AUTOSAR XML (schema 00044)
package /E40_Platform_System_SystemPackage/Components
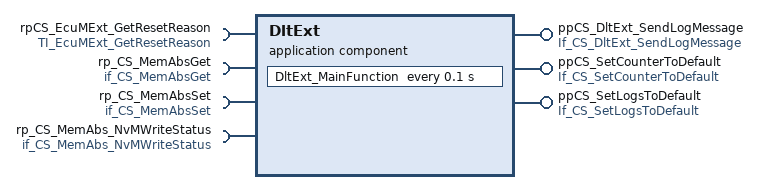
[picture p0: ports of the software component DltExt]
  application sw component type DltExt
    provide port ppCS_DltExt_SendLogMessage: server-com-spec{operation=SendLogMessage, queue-length=1}, provided-interface=If_CS_DltExt_SendLogMessage
    provide port ppCS_SetCounterToDefault: server-com-spec{operation=SetCounterToDefault, queue-length=1}, provided-interface=If_CS_SetCounterToDefault
    provide port ppCS_SetLogsToDefault: server-com-spec{operation=SetLogsToDefault, queue-length=1}, provided-interface=If_CS_SetLogsToDefault
    4 x require port:
      rpCS_EcuMExt_GetResetReason: client-com-spec=EcuMExt_GetResetReason, required-interface=TI_EcuMExt_GetResetReason
      rp_CS_MemAbsGet: required-interface=if_CS_MemAbsGet
        required-com-specs:
          Get_BsConst_Audio_Element
          Get_BsConst_Communication_Element
          Get_BsConst_EngOffTimer_Element
          Get_BsConst_FuelGauge_Element
          Get_BsConst_Illumination_Element
          Get_BsConst_OilGauge_Element
          Get_BsConst_PowerGauge_Element
          Get_BsConst_Power_Element
          Get_BsConst_RealTimeClock_Element
          Get_BsConst_ServiceReminder_Element
          Get_BsConst_SpeedoGauge_Element
          Get_BsConst_TachoGauge_Element
          Get_BsConst_TempGauge_Element
          Get_BsConst_TripComputer_Element
          Get_BsConst_Warning_Element
          Get_BsCys_Certicificate_Element
          Get_BsDiag_Dtc_Element
          Get_BsDiag_ErrorRecord_Element
          Get_BsFuSa_Audio_Element
          Get_BsFuSa_Communication_Element
          Get_BsFuSa_Config_Element
          Get_BsFuSa_Display_Element
          Get_BsFuSa_Power_Element
          Get_BsFuSa_Warning_Element
          Get_BsFusa_Fota_Element
          Get_BsReten_Audio_Element
          Get_BsReten_Communication_Element
          Get_BsReten_Display_Element
          Get_BsReten_Gauges_Element
          Get_BsReten_Illumination_Element
          Get_BsReten_Odometer_Element
          Get_BsReten_Personalization_Element
          Get_BsReten_Power_Element
          Get_BsReten_RealTimeClock_Element
          Get_BsReten_Tripcomputer_Element
          Get_BsReten_VisDlt_Element
          Get_BsReten_Warning_Element
          Get_BsRt_CusDlt_Element
          Get_BsRt_FuelGauge_Element
          Get_BsRt_Illumination_Element
          Get_BsRt_Odometer_Element
          Get_BsRt_OilGauge_Element
          Get_BsRt_Personalization_Element
          Get_BsRt_PowerGauge_Element
          Get_BsRt_RealTimeClock_Element
          Get_BsRt_SpeedoGauge_Element
          Get_BsRt_TachoGauge_Element
          Get_BsRt_TempGauge_Element
          Get_BsRt_TripComputer_Element
          Get_BsRt_Warning_Element
          Get_BsShare_EcuPartNumber_Element
          Get_BsShare_SwUpdFotaFinPrint_Element
          Get_BsShare_SwUpdFotaMode_Element
          Get_BsShare_SwUpdFotaStatus_Element
          Get_BsShare_SwUpdFotadecrypt_Element
          Get_BsShare_SwUpdReflash_Element
          Get_BsShare_VehicleConfig_Element
          Get_BsShare_VisMeet_Element
          Get_RefCys_Certicificate1_Element
          Get_RefCys_Certicificate_Element
      rp_CS_MemAbsSet: required-interface=if_CS_MemAbsSet
        required-com-specs:
          Set_BsConst_Audio_Element
          Set_BsConst_Communication_Element
          Set_BsConst_EngOffTimer_Element
          Set_BsConst_FuelGauge_Element
          Set_BsConst_Illumination_Element
          Set_BsConst_OilGauge_Element
          Set_BsConst_PowerGauge_Element
          Set_BsConst_Power_Element
          Set_BsConst_RealTimeClock_Element
          Set_BsConst_ServiceReminder_Element
          Set_BsConst_SpeedoGauge_Element
          Set_BsConst_TachoGauge_Element
          Set_BsConst_TempGauge_Element
          Set_BsConst_TripComputer_Element
          Set_BsConst_Warning_Element
          Set_BsCys_Certicificate_Element
          Set_BsDiag_Dtc_Element
          Set_BsDiag_ErrorRecord_Element
          Set_BsFuSa_Audio_Element
          Set_BsFuSa_Communication_Element
          Set_BsFuSa_Config_Element
          Set_BsFuSa_Display_Element
          Set_BsFuSa_Power_Element
          Set_BsFuSa_Warning_Element
          Set_BsFusa_Fota_Element
          Set_BsReten_Audio_Element
          Set_BsReten_Communication_Element
          Set_BsReten_Display_Element
          Set_BsReten_Gauges_Element
          Set_BsReten_Illumination_Element
          Set_BsReten_Odometer_Element
          Set_BsReten_Personalization_Element
          Set_BsReten_Power_Element
          Set_BsReten_RealTimeClock_Element
          Set_BsReten_Tripcomputer_Element
          Set_BsReten_VisDlt_Element
          Set_BsReten_Warning_Element
          Set_BsRt_CusDlt_Element
          Set_BsRt_FuelGauge_Element
          Set_BsRt_Illumination_Element
          Set_BsRt_Odometer_Element
          Set_BsRt_OilGauge_Element
          Set_BsRt_Personalization_Element
          Set_BsRt_PowerGauge_Element
          Set_BsRt_RealTimeClock_Element
          Set_BsRt_SpeedoGauge_Element
          Set_BsRt_TachoGauge_Element
          Set_BsRt_TempGauge_Element
          Set_BsRt_TripComputer_Element
          Set_BsRt_Warning_Element
          Set_BsShare_EcuPartNumber_Element
          Set_BsShare_SwUpdFotaFinPrint_Element
          Set_BsShare_SwUpdFotaMode_Element
          Set_BsShare_SwUpdFotaStatus_Element
          Set_BsShare_SwUpdFotadecrypt_Element
          Set_BsShare_SwUpdReflash_Element
          Set_BsShare_VehicleConfig_Element
          Set_BsShare_VisMeet_Element
          Set_RefCys_Certicificate1_Element
          Set_RefCys_Certicificate_Element
      rp_CS_MemAbs_NvMWriteStatus: client-com-spec=NvmWriteStatus, required-interface=if_CS_MemAbs_NvMWriteStatus
    behavior IB_DltExt
      timing event TEDltExt_MainFunction: start-on-event=DltExt_MainFunction, period=0.1
      operation invoked event OIE_ppCS_DltExt_SendLogMessage_DltExt_SendLogMessageTrigBySendLogMessage: start-on-event=DltExt_SendLogMessage, operation=ppCS_DltExt_SendLogMessage.SendLogMessage
      operation invoked event OIE_ppCS_SetCounterToDefault_DltExt_SetCounterToDefaultTrigBySetCounterToDefault: start-on-event=DltExt_SetCounterToDefault, operation=ppCS_SetCounterToDefault.SetCounterToDefault
      operation invoked event OIE_ppCS_SetLogsToDefault_DltExt_SetLogsToDefaultTrigBySetLogsToDefault: start-on-event=DltExt_SetLogsToDefault, operation=ppCS_SetLogsToDefault.SetLogsToDefault
      port-api-options:
        enable-take-address=false, indirect-api=false, port=ppCS_DltExt_SendLogMessage
        enable-take-address=false, indirect-api=false, port=ppCS_SetCounterToDefault
        enable-take-address=false, indirect-api=false, port=ppCS_SetLogsToDefault
        enable-take-address=false, indirect-api=false, port=rpCS_EcuMExt_GetResetReason
        enable-take-address=false, indirect-api=false, port=rp_CS_MemAbsGet
        enable-take-address=false, indirect-api=false, port=rp_CS_MemAbsSet
        enable-take-address=false, indirect-api=false, port=rp_CS_MemAbs_NvMWriteStatus
      4 x runnable, all with can-be-invoked-concurrently=true:
        DltExt_MainFunction
          122 x sync call:
            OA_rpCS_EcuMExt_GetResetReason_EcuMExt_GetResetReason: operation=rpCS_EcuMExt_GetResetReason.EcuMExt_GetResetReason
            OA_rp_CS_MemAbsGet_Get_BsShare_SwUpdReflash_Element: operation=rp_CS_MemAbsGet.Get_BsShare_SwUpdReflash_Element
            OA_rp_CS_MemAbsGet_Get_BsShare_SwUpdFotaMode_Element: operation=rp_CS_MemAbsGet.Get_BsShare_SwUpdFotaMode_Element
            OA_rp_CS_MemAbsGet_Get_BsShare_SwUpdFotaFinPrint_Element: operation=rp_CS_MemAbsGet.Get_BsShare_SwUpdFotaFinPrint_Element
            OA_rp_CS_MemAbsGet_Get_BsShare_SwUpdFotaStatus_Element: operation=rp_CS_MemAbsGet.Get_BsShare_SwUpdFotaStatus_Element
            OA_rp_CS_MemAbsGet_Get_BsShare_SwUpdFotadecrypt_Element: operation=rp_CS_MemAbsGet.Get_BsShare_SwUpdFotadecrypt_Element
            OA_rp_CS_MemAbsGet_Get_BsShare_EcuPartNumber_Element: operation=rp_CS_MemAbsGet.Get_BsShare_EcuPartNumber_Element
            OA_rp_CS_MemAbsGet_Get_BsShare_VisMeet_Element: operation=rp_CS_MemAbsGet.Get_BsShare_VisMeet_Element
            OA_rp_CS_MemAbsGet_Get_BsShare_VehicleConfig_Element: operation=rp_CS_MemAbsGet.Get_BsShare_VehicleConfig_Element
            OA_rp_CS_MemAbsGet_Get_BsConst_SpeedoGauge_Element: operation=rp_CS_MemAbsGet.Get_BsConst_SpeedoGauge_Element
            OA_rp_CS_MemAbsGet_Get_BsConst_TachoGauge_Element: operation=rp_CS_MemAbsGet.Get_BsConst_TachoGauge_Element
            OA_rp_CS_MemAbsGet_Get_BsConst_FuelGauge_Element: operation=rp_CS_MemAbsGet.Get_BsConst_FuelGauge_Element
            OA_rp_CS_MemAbsGet_Get_BsConst_TempGauge_Element: operation=rp_CS_MemAbsGet.Get_BsConst_TempGauge_Element
            OA_rp_CS_MemAbsGet_Get_BsConst_PowerGauge_Element: operation=rp_CS_MemAbsGet.Get_BsConst_PowerGauge_Element
            OA_rp_CS_MemAbsGet_Get_BsConst_OilGauge_Element: operation=rp_CS_MemAbsGet.Get_BsConst_OilGauge_Element
            OA_rp_CS_MemAbsGet_Get_BsConst_TripComputer_Element: operation=rp_CS_MemAbsGet.Get_BsConst_TripComputer_Element
            OA_rp_CS_MemAbsGet_Get_BsConst_Illumination_Element: operation=rp_CS_MemAbsGet.Get_BsConst_Illumination_Element
            OA_rp_CS_MemAbsGet_Get_BsConst_Audio_Element: operation=rp_CS_MemAbsGet.Get_BsConst_Audio_Element
            OA_rp_CS_MemAbsGet_Get_BsConst_Warning_Element: operation=rp_CS_MemAbsGet.Get_BsConst_Warning_Element
            OA_rp_CS_MemAbsGet_Get_BsConst_RealTimeClock_Element: operation=rp_CS_MemAbsGet.Get_BsConst_RealTimeClock_Element
            OA_rp_CS_MemAbsGet_Get_BsConst_Communication_Element: operation=rp_CS_MemAbsGet.Get_BsConst_Communication_Element
            OA_rp_CS_MemAbsGet_Get_BsConst_Power_Element: operation=rp_CS_MemAbsGet.Get_BsConst_Power_Element
            OA_rp_CS_MemAbsGet_Get_BsConst_ServiceReminder_Element: operation=rp_CS_MemAbsGet.Get_BsConst_ServiceReminder_Element
            OA_rp_CS_MemAbsGet_Get_BsConst_EngOffTimer_Element: operation=rp_CS_MemAbsGet.Get_BsConst_EngOffTimer_Element
            OA_rp_CS_MemAbsGet_Get_BsFuSa_Warning_Element: operation=rp_CS_MemAbsGet.Get_BsFuSa_Warning_Element
            OA_rp_CS_MemAbsGet_Get_BsFuSa_Power_Element: operation=rp_CS_MemAbsGet.Get_BsFuSa_Power_Element
            OA_rp_CS_MemAbsGet_Get_BsFuSa_Display_Element: operation=rp_CS_MemAbsGet.Get_BsFuSa_Display_Element
            OA_rp_CS_MemAbsGet_Get_BsFuSa_Audio_Element: operation=rp_CS_MemAbsGet.Get_BsFuSa_Audio_Element
            OA_rp_CS_MemAbsGet_Get_BsFuSa_Communication_Element: operation=rp_CS_MemAbsGet.Get_BsFuSa_Communication_Element
            OA_rp_CS_MemAbsGet_Get_BsFusa_Fota_Element: operation=rp_CS_MemAbsGet.Get_BsFusa_Fota_Element
            OA_rp_CS_MemAbsGet_Get_BsFuSa_Config_Element: operation=rp_CS_MemAbsGet.Get_BsFuSa_Config_Element
            OA_rp_CS_MemAbsGet_Get_BsCys_Certicificate_Element: operation=rp_CS_MemAbsGet.Get_BsCys_Certicificate_Element
            OA_rp_CS_MemAbsGet_Get_RefCys_Certicificate_Element: operation=rp_CS_MemAbsGet.Get_RefCys_Certicificate_Element
            OA_rp_CS_MemAbsGet_Get_RefCys_Certicificate1_Element: operation=rp_CS_MemAbsGet.Get_RefCys_Certicificate1_Element
            OA_rp_CS_MemAbsGet_Get_BsRt_Odometer_Element: operation=rp_CS_MemAbsGet.Get_BsRt_Odometer_Element
            OA_rp_CS_MemAbsGet_Get_BsRt_SpeedoGauge_Element: operation=rp_CS_MemAbsGet.Get_BsRt_SpeedoGauge_Element
            OA_rp_CS_MemAbsGet_Get_BsRt_TachoGauge_Element: operation=rp_CS_MemAbsGet.Get_BsRt_TachoGauge_Element
            OA_rp_CS_MemAbsGet_Get_BsRt_FuelGauge_Element: operation=rp_CS_MemAbsGet.Get_BsRt_FuelGauge_Element
            OA_rp_CS_MemAbsGet_Get_BsRt_TempGauge_Element: operation=rp_CS_MemAbsGet.Get_BsRt_TempGauge_Element
            OA_rp_CS_MemAbsGet_Get_BsRt_PowerGauge_Element: operation=rp_CS_MemAbsGet.Get_BsRt_PowerGauge_Element
            OA_rp_CS_MemAbsGet_Get_BsRt_OilGauge_Element: operation=rp_CS_MemAbsGet.Get_BsRt_OilGauge_Element
            OA_rp_CS_MemAbsGet_Get_BsRt_TripComputer_Element: operation=rp_CS_MemAbsGet.Get_BsRt_TripComputer_Element
            OA_rp_CS_MemAbsGet_Get_BsRt_Warning_Element: operation=rp_CS_MemAbsGet.Get_BsRt_Warning_Element
            OA_rp_CS_MemAbsGet_Get_BsRt_RealTimeClock_Element: operation=rp_CS_MemAbsGet.Get_BsRt_RealTimeClock_Element
            OA_rp_CS_MemAbsGet_Get_BsRt_Personalization_Element: operation=rp_CS_MemAbsGet.Get_BsRt_Personalization_Element
            OA_rp_CS_MemAbsGet_Get_BsRt_Illumination_Element: operation=rp_CS_MemAbsGet.Get_BsRt_Illumination_Element
            OA_rp_CS_MemAbsGet_Get_BsRt_CusDlt_Element: operation=rp_CS_MemAbsGet.Get_BsRt_CusDlt_Element
            OA_rp_CS_MemAbsGet_Get_BsReten_Odometer_Element: operation=rp_CS_MemAbsGet.Get_BsReten_Odometer_Element
            OA_rp_CS_MemAbsGet_Get_BsReten_Gauges_Element: operation=rp_CS_MemAbsGet.Get_BsReten_Gauges_Element
            OA_rp_CS_MemAbsGet_Get_BsReten_Tripcomputer_Element: operation=rp_CS_MemAbsGet.Get_BsReten_Tripcomputer_Element
            OA_rp_CS_MemAbsGet_Get_BsReten_Illumination_Element: operation=rp_CS_MemAbsGet.Get_BsReten_Illumination_Element
            OA_rp_CS_MemAbsGet_Get_BsReten_Audio_Element: operation=rp_CS_MemAbsGet.Get_BsReten_Audio_Element
            OA_rp_CS_MemAbsGet_Get_BsReten_Warning_Element: operation=rp_CS_MemAbsGet.Get_BsReten_Warning_Element
            OA_rp_CS_MemAbsGet_Get_BsReten_RealTimeClock_Element: operation=rp_CS_MemAbsGet.Get_BsReten_RealTimeClock_Element
            OA_rp_CS_MemAbsGet_Get_BsReten_Communication_Element: operation=rp_CS_MemAbsGet.Get_BsReten_Communication_Element
            OA_rp_CS_MemAbsGet_Get_BsReten_Personalization_Element: operation=rp_CS_MemAbsGet.Get_BsReten_Personalization_Element
            OA_rp_CS_MemAbsGet_Get_BsReten_VisDlt_Element: operation=rp_CS_MemAbsGet.Get_BsReten_VisDlt_Element
            OA_rp_CS_MemAbsGet_Get_BsReten_Power_Element: operation=rp_CS_MemAbsGet.Get_BsReten_Power_Element
            OA_rp_CS_MemAbsGet_Get_BsReten_Display_Element: operation=rp_CS_MemAbsGet.Get_BsReten_Display_Element
            OA_rp_CS_MemAbsGet_Get_BsDiag_ErrorRecord_Element: operation=rp_CS_MemAbsGet.Get_BsDiag_ErrorRecord_Element
            OA_rp_CS_MemAbsGet_Get_BsDiag_Dtc_Element: operation=rp_CS_MemAbsGet.Get_BsDiag_Dtc_Element
            OA_rp_CS_MemAbsSet_Set_BsShare_SwUpdReflash_Element: operation=rp_CS_MemAbsSet.Set_BsShare_SwUpdReflash_Element
            OA_rp_CS_MemAbsSet_Set_BsShare_SwUpdFotaMode_Element: operation=rp_CS_MemAbsSet.Set_BsShare_SwUpdFotaMode_Element
            OA_rp_CS_MemAbsSet_Set_BsShare_SwUpdFotaFinPrint_Element: operation=rp_CS_MemAbsSet.Set_BsShare_SwUpdFotaFinPrint_Element
            OA_rp_CS_MemAbsSet_Set_BsShare_SwUpdFotaStatus_Element: operation=rp_CS_MemAbsSet.Set_BsShare_SwUpdFotaStatus_Element
            OA_rp_CS_MemAbsSet_Set_BsShare_SwUpdFotadecrypt_Element: operation=rp_CS_MemAbsSet.Set_BsShare_SwUpdFotadecrypt_Element
            OA_rp_CS_MemAbsSet_Set_BsShare_EcuPartNumber_Element: operation=rp_CS_MemAbsSet.Set_BsShare_EcuPartNumber_Element
            OA_rp_CS_MemAbsSet_Set_BsShare_VisMeet_Element: operation=rp_CS_MemAbsSet.Set_BsShare_VisMeet_Element
            OA_rp_CS_MemAbsSet_Set_BsShare_VehicleConfig_Element: operation=rp_CS_MemAbsSet.Set_BsShare_VehicleConfig_Element
            OA_rp_CS_MemAbsSet_Set_BsConst_SpeedoGauge_Element: operation=rp_CS_MemAbsSet.Set_BsConst_SpeedoGauge_Element
            OA_rp_CS_MemAbsSet_Set_BsConst_TachoGauge_Element: operation=rp_CS_MemAbsSet.Set_BsConst_TachoGauge_Element
            OA_rp_CS_MemAbsSet_Set_BsConst_FuelGauge_Element: operation=rp_CS_MemAbsSet.Set_BsConst_FuelGauge_Element
            OA_rp_CS_MemAbsSet_Set_BsConst_TempGauge_Element: operation=rp_CS_MemAbsSet.Set_BsConst_TempGauge_Element
            OA_rp_CS_MemAbsSet_Set_BsConst_PowerGauge_Element: operation=rp_CS_MemAbsSet.Set_BsConst_PowerGauge_Element
            OA_rp_CS_MemAbsSet_Set_BsConst_OilGauge_Element: operation=rp_CS_MemAbsSet.Set_BsConst_OilGauge_Element
            OA_rp_CS_MemAbsSet_Set_BsConst_TripComputer_Element: operation=rp_CS_MemAbsSet.Set_BsConst_TripComputer_Element
            OA_rp_CS_MemAbsSet_Set_BsConst_Illumination_Element: operation=rp_CS_MemAbsSet.Set_BsConst_Illumination_Element
            OA_rp_CS_MemAbsSet_Set_BsConst_Audio_Element: operation=rp_CS_MemAbsSet.Set_BsConst_Audio_Element
            OA_rp_CS_MemAbsSet_Set_BsConst_Warning_Element: operation=rp_CS_MemAbsSet.Set_BsConst_Warning_Element
            OA_rp_CS_MemAbsSet_Set_BsConst_RealTimeClock_Element: operation=rp_CS_MemAbsSet.Set_BsConst_RealTimeClock_Element
            OA_rp_CS_MemAbsSet_Set_BsConst_Communication_Element: operation=rp_CS_MemAbsSet.Set_BsConst_Communication_Element
            OA_rp_CS_MemAbsSet_Set_BsConst_Power_Element: operation=rp_CS_MemAbsSet.Set_BsConst_Power_Element
            OA_rp_CS_MemAbsSet_Set_BsConst_ServiceReminder_Element: operation=rp_CS_MemAbsSet.Set_BsConst_ServiceReminder_Element
            OA_rp_CS_MemAbsSet_Set_BsConst_EngOffTimer_Element: operation=rp_CS_MemAbsSet.Set_BsConst_EngOffTimer_Element
            OA_rp_CS_MemAbsSet_Set_BsFuSa_Warning_Element: operation=rp_CS_MemAbsSet.Set_BsFuSa_Warning_Element
            OA_rp_CS_MemAbsSet_Set_BsFuSa_Power_Element: operation=rp_CS_MemAbsSet.Set_BsFuSa_Power_Element
            OA_rp_CS_MemAbsSet_Set_BsFuSa_Display_Element: operation=rp_CS_MemAbsSet.Set_BsFuSa_Display_Element
            OA_rp_CS_MemAbsSet_Set_BsFuSa_Audio_Element: operation=rp_CS_MemAbsSet.Set_BsFuSa_Audio_Element
            OA_rp_CS_MemAbsSet_Set_BsFuSa_Communication_Element: operation=rp_CS_MemAbsSet.Set_BsFuSa_Communication_Element
            OA_rp_CS_MemAbsSet_Set_BsFusa_Fota_Element: operation=rp_CS_MemAbsSet.Set_BsFusa_Fota_Element
            OA_rp_CS_MemAbsSet_Set_BsFuSa_Config_Element: operation=rp_CS_MemAbsSet.Set_BsFuSa_Config_Element
            OA_rp_CS_MemAbsSet_Set_BsCys_Certicificate_Element: operation=rp_CS_MemAbsSet.Set_BsCys_Certicificate_Element
            OA_rp_CS_MemAbsSet_Set_RefCys_Certicificate_Element: operation=rp_CS_MemAbsSet.Set_RefCys_Certicificate_Element
            OA_rp_CS_MemAbsSet_Set_RefCys_Certicificate1_Element: operation=rp_CS_MemAbsSet.Set_RefCys_Certicificate1_Element
            OA_rp_CS_MemAbsSet_Set_BsRt_Odometer_Element: operation=rp_CS_MemAbsSet.Set_BsRt_Odometer_Element
            OA_rp_CS_MemAbsSet_Set_BsRt_SpeedoGauge_Element: operation=rp_CS_MemAbsSet.Set_BsRt_SpeedoGauge_Element
            OA_rp_CS_MemAbsSet_Set_BsRt_TachoGauge_Element: operation=rp_CS_MemAbsSet.Set_BsRt_TachoGauge_Element
            OA_rp_CS_MemAbsSet_Set_BsRt_FuelGauge_Element: operation=rp_CS_MemAbsSet.Set_BsRt_FuelGauge_Element
            OA_rp_CS_MemAbsSet_Set_BsRt_TempGauge_Element: operation=rp_CS_MemAbsSet.Set_BsRt_TempGauge_Element
            OA_rp_CS_MemAbsSet_Set_BsRt_PowerGauge_Element: operation=rp_CS_MemAbsSet.Set_BsRt_PowerGauge_Element
            OA_rp_CS_MemAbsSet_Set_BsRt_OilGauge_Element: operation=rp_CS_MemAbsSet.Set_BsRt_OilGauge_Element
            OA_rp_CS_MemAbsSet_Set_BsRt_TripComputer_Element: operation=rp_CS_MemAbsSet.Set_BsRt_TripComputer_Element
            OA_rp_CS_MemAbsSet_Set_BsRt_Warning_Element: operation=rp_CS_MemAbsSet.Set_BsRt_Warning_Element
            OA_rp_CS_MemAbsSet_Set_BsRt_RealTimeClock_Element: operation=rp_CS_MemAbsSet.Set_BsRt_RealTimeClock_Element
            OA_rp_CS_MemAbsSet_Set_BsRt_Personalization_Element: operation=rp_CS_MemAbsSet.Set_BsRt_Personalization_Element
            OA_rp_CS_MemAbsSet_Set_BsRt_Illumination_Element: operation=rp_CS_MemAbsSet.Set_BsRt_Illumination_Element
            OA_rp_CS_MemAbsSet_Set_BsRt_CusDlt_Element: operation=rp_CS_MemAbsSet.Set_BsRt_CusDlt_Element
            OA_rp_CS_MemAbsSet_Set_BsReten_Odometer_Element: operation=rp_CS_MemAbsSet.Set_BsReten_Odometer_Element
            OA_rp_CS_MemAbsSet_Set_BsReten_Gauges_Element: operation=rp_CS_MemAbsSet.Set_BsReten_Gauges_Element
            OA_rp_CS_MemAbsSet_Set_BsReten_Tripcomputer_Element: operation=rp_CS_MemAbsSet.Set_BsReten_Tripcomputer_Element
            OA_rp_CS_MemAbsSet_Set_BsReten_Illumination_Element: operation=rp_CS_MemAbsSet.Set_BsReten_Illumination_Element
            OA_rp_CS_MemAbsSet_Set_BsReten_Audio_Element: operation=rp_CS_MemAbsSet.Set_BsReten_Audio_Element
            OA_rp_CS_MemAbsSet_Set_BsReten_Warning_Element: operation=rp_CS_MemAbsSet.Set_BsReten_Warning_Element
            OA_rp_CS_MemAbsSet_Set_BsReten_RealTimeClock_Element: operation=rp_CS_MemAbsSet.Set_BsReten_RealTimeClock_Element
            OA_rp_CS_MemAbsSet_Set_BsReten_Communication_Element: operation=rp_CS_MemAbsSet.Set_BsReten_Communication_Element
            OA_rp_CS_MemAbsSet_Set_BsReten_Personalization_Element: operation=rp_CS_MemAbsSet.Set_BsReten_Personalization_Element
            OA_rp_CS_MemAbsSet_Set_BsReten_VisDlt_Element: operation=rp_CS_MemAbsSet.Set_BsReten_VisDlt_Element
            OA_rp_CS_MemAbsSet_Set_BsReten_Power_Element: operation=rp_CS_MemAbsSet.Set_BsReten_Power_Element
            OA_rp_CS_MemAbsSet_Set_BsReten_Display_Element: operation=rp_CS_MemAbsSet.Set_BsReten_Display_Element
            OA_rp_CS_MemAbsSet_Set_BsDiag_ErrorRecord_Element: operation=rp_CS_MemAbsSet.Set_BsDiag_ErrorRecord_Element
            OA_rp_CS_MemAbsSet_Set_BsDiag_Dtc_Element: operation=rp_CS_MemAbsSet.Set_BsDiag_Dtc_Element
            OA_rp_CS_MemAbs_NvMWriteStatus_NvmWriteStatus: operation=rp_CS_MemAbs_NvMWriteStatus.NvmWriteStatus
        DltExt_SendLogMessage
        DltExt_SetCounterToDefault
        DltExt_SetLogsToDefault
  swc implementation IMPL_DltExt: behavior=IB_DltExt
